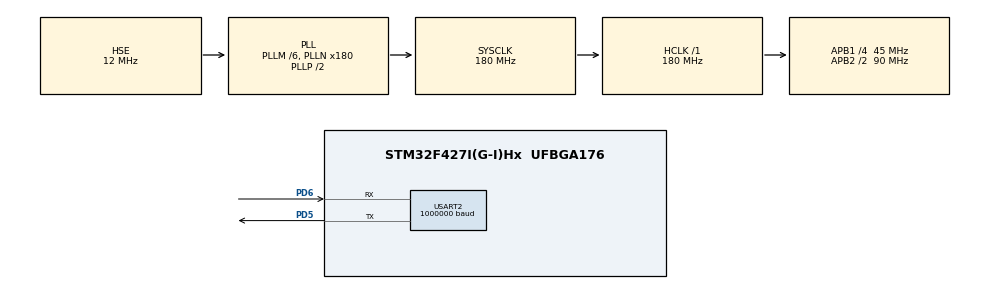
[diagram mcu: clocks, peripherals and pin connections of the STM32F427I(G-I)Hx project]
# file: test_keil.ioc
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Dma.Request0=USART2_RX
Dma.Request1=USART2_TX
Dma.USART2_RX.0.Direction=DMA_PERIPH_TO_MEMORY
Dma.USART2_RX.0.FIFOMode=DMA_FIFOMODE_ENABLE
Dma.USART2_RX.0.FIFOThreshold=DMA_FIFO_THRESHOLD_FULL
Dma.USART2_RX.0.Instance=DMA1_Stream5
Dma.USART2_RX.0.MemBurst=DMA_MBURST_SINGLE
Dma.USART2_RX.0.MemDataAlignment=DMA_MDATAALIGN_BYTE
Dma.USART2_RX.0.MemInc=DMA_MINC_ENABLE
Dma.USART2_RX.0.Mode=DMA_NORMAL
Dma.USART2_RX.0.PeriphBurst=DMA_PBURST_SINGLE
Dma.USART2_RX.0.PeriphDataAlignment=DMA_PDATAALIGN_BYTE
Dma.USART2_RX.0.PeriphInc=DMA_PINC_DISABLE
Dma.USART2_RX.0.Priority=DMA_PRIORITY_LOW
Dma.USART2_TX.1.Direction=DMA_MEMORY_TO_PERIPH
Dma.USART2_TX.1.FIFOMode=DMA_FIFOMODE_ENABLE
Dma.USART2_TX.1.FIFOThreshold=DMA_FIFO_THRESHOLD_FULL
Dma.USART2_TX.1.Instance=DMA1_Stream6
Dma.USART2_TX.1.MemBurst=DMA_MBURST_SINGLE
Dma.USART2_TX.1.MemDataAlignment=DMA_MDATAALIGN_BYTE
Dma.USART2_TX.1.MemInc=DMA_MINC_ENABLE
Dma.USART2_TX.1.Mode=DMA_NORMAL
Dma.USART2_TX.1.PeriphBurst=DMA_PBURST_SINGLE
Dma.USART2_TX.1.PeriphDataAlignment=DMA_PDATAALIGN_BYTE
Dma.USART2_TX.1.PeriphInc=DMA_PINC_DISABLE
Dma.USART2_TX.1.Priority=DMA_PRIORITY_LOW
Mcu.Family=STM32F4
Mcu.Name=STM32F427I(G-I)Hx
Mcu.Package=UFBGA176
NVIC.DMA1_Stream5_IRQn=true\:0\:0\:false\:false\:true\:false\:true\:true
NVIC.DMA1_Stream6_IRQn=true\:0\:0\:false\:false\:true\:false\:true\:true
NVIC.PriorityGroup=NVIC_PRIORITYGROUP_4
NVIC.TIM4_IRQn=true\:0\:0\:false\:false\:true\:true\:true\:true
NVIC.USART2_IRQn=true\:0\:0\:false\:false\:true\:true\:true\:true
PA13.Mode=Serial_Wire
PA13.Signal=SYS_JTMS-SWDIO
PA14.Mode=Serial_Wire
PA14.Signal=SYS_JTCK-SWCLK
PD5.Mode=Asynchronous
PD5.Signal=USART2_TX
PD6.Mode=Asynchronous
PD6.Signal=USART2_RX
PH0/OSC_IN.Mode=HSE-External-Oscillator
PH0/OSC_IN.Signal=RCC_OSC_IN
PH1/OSC_OUT.Mode=HSE-External-Oscillator
PH1/OSC_OUT.Signal=RCC_OSC_OUT
ProjectManager.HeapSize=0x200
ProjectManager.StackSize=0x400
ProjectManager.TargetToolchain=MDK-ARM V5.32
RCC.48MHZClocksFreq_Value=90000000
RCC.AHBFreq_Value=180000000
RCC.APB1CLKDivider=RCC_HCLK_DIV4
RCC.APB1Freq_Value=45000000
RCC.APB1TimFreq_Value=90000000
RCC.APB2CLKDivider=RCC_HCLK_DIV2
RCC.APB2Freq_Value=90000000
RCC.APB2TimFreq_Value=180000000
RCC.CortexFreq_Value=180000000
RCC.HCLKFreq_Value=180000000
RCC.HSE_VALUE=12000000
RCC.HSI_VALUE=16000000
RCC.LSE_VALUE=32768
RCC.PLLM=6
RCC.PLLN=180
RCC.PLLSourceVirtual=RCC_PLLSOURCE_HSE
RCC.SYSCLKFreq_VALUE=180000000
RCC.SYSCLKSource=RCC_SYSCLKSOURCE_PLLCLK
RCC.VCOOutputFreq_Value=360000000
STMicroelectronics.X-CUBE-ALGOBUILD.1.4.0.LibraryCcDSPOoLibraryJjDSPOoLibrary=true
TIM4.Period=1000-1
TIM4.Prescaler=90-1
USART2.BaudRate=1000000
USART2.VirtualMode=VM_ASYNC
VP_STMicroelectronics.X-CUBE-ALGOBUILD_VS_DSPOoLibraryJjLibrary_1.4.0_1.4.0.Mode=DSPOoLibraryJjLibrary
VP_TIM4_VS_ClockSourceINT.Mode=Internal
board=custom

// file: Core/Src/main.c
/* USER CODE BEGIN Header */
/**
  ******************************************************************************
  * @file           : main.c
  * @brief          : Main program body
  ******************************************************************************
  * @attention
  *
  * Copyright (c) 2024 STMicroelectronics.
  * All rights reserved.
  *
  * This software is licensed under terms that can be found in the LICENSE file
  * in the root directory of this software component.
  * If no LICENSE file comes with this software, it is provided AS-IS.
  *
  ******************************************************************************
  */
/* USER CODE END Header */
#include "main.h"
#include "dma.h"
#include "tim.h"
#include "usart.h"
#include "gpio.h"

/* USER CODE BEGIN Includes */

#include <math.h>
#include "arm_math.h"
#include "dvc_serialplot.h"

/* USER CODE END Includes */

/* USER CODE BEGIN PV */

float flag = 0, i = 0, j = 0;
Class_Serialplot serialplot;

/* USER CODE END PV */

void SystemClock_Config(void);
/* USER CODE BEGIN PFP */

void uart_null_callback(uint8_t *Buffer, uint16_t Length)
{

}

void HAL_TIM_PeriodElapsedCallback(TIM_HandleTypeDef *htim)
{
  if(htim->Instance == TIM4)
  {
    serialplot.TIM_Write_PeriodElapsedCallback();
    TIM_UART_PeriodElapsedCallback();
  }
}

/* USER CODE END PFP */

int main(void)
{

  /* MCU Configuration--------------------------------------------------------*/

  /* Reset of all peripherals, Initializes the Flash interface and the Systick. */
  HAL_Init();

  /* Configure the system clock */
  SystemClock_Config();

  /* Initialize all configured peripherals */
  MX_GPIO_Init();
  MX_DMA_Init();
  MX_TIM4_Init();
  MX_USART2_UART_Init();
  /* USER CODE BEGIN 2 */

  UART_Init(&huart2, uart_null_callback, UART_BUFFER_SIZE);
  serialplot.Init(&huart2);
  serialplot.Set_Data(2, &flag, &i);

  HAL_TIM_Base_Start_IT(&htim4);

  /* USER CODE END 2 */

  /* Infinite loop */
  /* USER CODE BEGIN WHILE */
  while (1)
  {
    for(i = 0; i < 1000; i++)
    {
      for(j = 0; j < 1000; j++)
      {
        sin((float)(i + j));
      }
    }
    flag = 1;
    for(i = 0; i < 1000; i++)
    {
      for(j = 0; j < 1000; j++)
      {
        arm_sin_f32(i + j);
      }
    }
    flag = 0;
    /* USER CODE END WHILE */

  }
}

void SystemClock_Config(void)
{
  RCC_OscInitTypeDef RCC_OscInitStruct = {0};
  RCC_ClkInitTypeDef RCC_ClkInitStruct = {0};

  /** Configure the main internal regulator output voltage
  */
  __HAL_RCC_PWR_CLK_ENABLE();
  __HAL_PWR_VOLTAGESCALING_CONFIG(PWR_REGULATOR_VOLTAGE_SCALE1);

  /** Initializes the RCC Oscillators according to the specified parameters
  * in the RCC_OscInitTypeDef structure.
  */
  RCC_OscInitStruct.OscillatorType = RCC_OSCILLATORTYPE_HSE;
  RCC_OscInitStruct.HSEState = RCC_HSE_ON;
  RCC_OscInitStruct.PLL.PLLState = RCC_PLL_ON;
  RCC_OscInitStruct.PLL.PLLSource = RCC_PLLSOURCE_HSE;
  RCC_OscInitStruct.PLL.PLLM = 6;
  RCC_OscInitStruct.PLL.PLLN = 180;
  RCC_OscInitStruct.PLL.PLLP = RCC_PLLP_DIV2;
  RCC_OscInitStruct.PLL.PLLQ = 4;
  if (HAL_RCC_OscConfig(&RCC_OscInitStruct) != HAL_OK)
  {
    Error_Handler();
  }

  /** Activate the Over-Drive mode
  */
  if (HAL_PWREx_EnableOverDrive() != HAL_OK)
  {
    Error_Handler();
  }

  /** Initializes the CPU, AHB and APB buses clocks
  */
  RCC_ClkInitStruct.ClockType = RCC_CLOCKTYPE_HCLK|RCC_CLOCKTYPE_SYSCLK
                              |RCC_CLOCKTYPE_PCLK1|RCC_CLOCKTYPE_PCLK2;
  RCC_ClkInitStruct.SYSCLKSource = RCC_SYSCLKSOURCE_PLLCLK;
  RCC_ClkInitStruct.AHBCLKDivider = RCC_SYSCLK_DIV1;
  RCC_ClkInitStruct.APB1CLKDivider = RCC_HCLK_DIV4;
  RCC_ClkInitStruct.APB2CLKDivider = RCC_HCLK_DIV2;

  if (HAL_RCC_ClockConfig(&RCC_ClkInitStruct, FLASH_LATENCY_5) != HAL_OK)
  {
    Error_Handler();
  }
}

void Error_Handler(void)
{
  __disable_irq();
  while (1)
  {
  }
}
